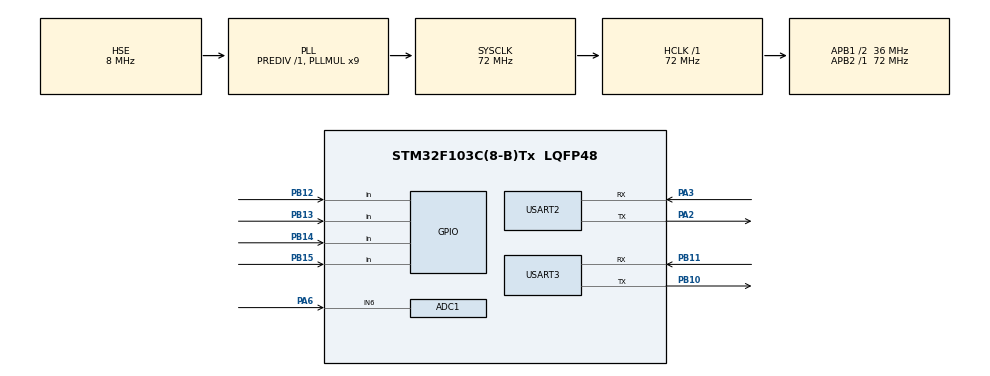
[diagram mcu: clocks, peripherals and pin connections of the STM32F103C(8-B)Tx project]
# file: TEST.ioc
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ADC1.Channel-0\#ChannelRegularConversion=ADC_CHANNEL_6
ADC1.ExternalTrigConv=ADC_EXTERNALTRIGCONV_T3_TRGO
ADC1.NbrOfConversionFlag=1
ADC1.Rank-0\#ChannelRegularConversion=1
ADC1.SamplingTime-0\#ChannelRegularConversion=ADC_SAMPLETIME_1CYCLE_5
ADC1.master=1
Dma.ADC1.2.Direction=DMA_PERIPH_TO_MEMORY
Dma.ADC1.2.Instance=DMA1_Channel1
Dma.ADC1.2.MemDataAlignment=DMA_MDATAALIGN_HALFWORD
Dma.ADC1.2.MemInc=DMA_MINC_ENABLE
Dma.ADC1.2.Mode=DMA_NORMAL
Dma.ADC1.2.PeriphDataAlignment=DMA_PDATAALIGN_HALFWORD
Dma.ADC1.2.PeriphInc=DMA_PINC_DISABLE
Dma.ADC1.2.Priority=DMA_PRIORITY_LOW
Dma.Request0=USART3_RX
Dma.Request1=USART3_TX
Dma.Request2=ADC1
Dma.USART3_RX.0.Direction=DMA_PERIPH_TO_MEMORY
Dma.USART3_RX.0.Instance=DMA1_Channel3
Dma.USART3_RX.0.MemDataAlignment=DMA_MDATAALIGN_BYTE
Dma.USART3_RX.0.MemInc=DMA_MINC_ENABLE
Dma.USART3_RX.0.Mode=DMA_CIRCULAR
Dma.USART3_RX.0.PeriphDataAlignment=DMA_PDATAALIGN_BYTE
Dma.USART3_RX.0.PeriphInc=DMA_PINC_DISABLE
Dma.USART3_RX.0.Priority=DMA_PRIORITY_HIGH
Dma.USART3_TX.1.Direction=DMA_MEMORY_TO_PERIPH
Dma.USART3_TX.1.Instance=DMA1_Channel2
Dma.USART3_TX.1.MemDataAlignment=DMA_MDATAALIGN_BYTE
Dma.USART3_TX.1.MemInc=DMA_MINC_ENABLE
Dma.USART3_TX.1.Mode=DMA_NORMAL
Dma.USART3_TX.1.PeriphDataAlignment=DMA_PDATAALIGN_BYTE
Dma.USART3_TX.1.PeriphInc=DMA_PINC_DISABLE
Dma.USART3_TX.1.Priority=DMA_PRIORITY_HIGH
Mcu.Family=STM32F1
Mcu.Name=STM32F103C(8-B)Tx
Mcu.Package=LQFP48
NVIC.DMA1_Channel1_IRQn=true\:0\:0\:false\:false\:true\:false\:true\:true
NVIC.DMA1_Channel2_IRQn=true\:0\:0\:false\:false\:true\:false\:true\:true
NVIC.DMA1_Channel3_IRQn=true\:0\:0\:false\:false\:true\:false\:true\:true
NVIC.PriorityGroup=NVIC_PRIORITYGROUP_4
NVIC.USART2_IRQn=true\:1\:0\:true\:false\:true\:true\:true\:true
NVIC.USART3_IRQn=true\:1\:0\:true\:false\:true\:false\:true\:true
PA13.Mode=Serial_Wire
PA13.Signal=SYS_JTMS-SWDIO
PA14.Mode=Serial_Wire
PA14.Signal=SYS_JTCK-SWCLK
PA2.Mode=Asynchronous
PA2.Signal=USART2_TX
PA3.Mode=Asynchronous
PA3.Signal=USART2_RX
PA6.Signal=ADCx_IN6
PB10.Mode=Asynchronous
PB10.Signal=USART3_TX
PB11.Mode=Asynchronous
PB11.Signal=USART3_RX
PB12.GPIO_PuPd=GPIO_PULLUP
PB12.Signal=GPIO_Input
PB13.GPIO_PuPd=GPIO_PULLUP
PB13.Signal=GPIO_Input
PB14.GPIO_PuPd=GPIO_PULLUP
PB14.Signal=GPIO_Input
PB15.GPIO_PuPd=GPIO_PULLUP
PB15.Signal=GPIO_Input
PD0-OSC_IN.Mode=HSE-External-Oscillator
PD0-OSC_IN.Signal=RCC_OSC_IN
PD1-OSC_OUT.Mode=HSE-External-Oscillator
PD1-OSC_OUT.Signal=RCC_OSC_OUT
ProjectManager.HeapSize=0x200
ProjectManager.StackSize=0x400
ProjectManager.TargetToolchain=MDK-ARM V5.32
RCC.ADCPresc=RCC_ADCPCLK2_DIV6
RCC.AHBFreq_Value=72000000
RCC.APB1CLKDivider=RCC_HCLK_DIV2
RCC.APB1Freq_Value=36000000
RCC.APB1TimFreq_Value=72000000
RCC.APB2Freq_Value=72000000
RCC.APB2TimFreq_Value=72000000
RCC.HCLKFreq_Value=72000000
RCC.PLLMUL=RCC_PLL_MUL9
RCC.PLLSourceVirtual=RCC_PLLSOURCE_HSE
RCC.SYSCLKFreq_VALUE=72000000
RCC.SYSCLKSource=RCC_SYSCLKSOURCE_PLLCLK
RCC.USBFreq_Value=72000000
SH.ADCx_IN6.0=ADC1_IN6,IN6
TIM3.AutoReloadPreload=TIM_AUTORELOAD_PRELOAD_ENABLE
TIM3.Period=10-1
TIM3.Prescaler=72-1
TIM3.TIM_MasterOutputTrigger=TIM_TRGO_UPDATE
USART2.VirtualMode=VM_ASYNC
USART3.VirtualMode=VM_ASYNC
VP_TIM3_VS_ClockSourceINT.Mode=Internal
board=custom

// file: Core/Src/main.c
/* USER CODE BEGIN Header */
/**
  ******************************************************************************
  * @file           : main.c
  * @brief          : Main program body
  ******************************************************************************
  * @attention
  *
  * Copyright (c) 2025 STMicroelectronics.
  * All rights reserved.
  *
  * This software is licensed under terms that can be found in the LICENSE file
  * in the root directory of this software component.
  * If no LICENSE file comes with this software, it is provided AS-IS.
  *
  ******************************************************************************
  */
/* USER CODE END Header */
#include "main.h"
#include "adc.h"
#include "dma.h"
#include "tim.h"
#include "usart.h"
#include "gpio.h"

/* USER CODE BEGIN Includes */

#include "user.h"

/* USER CODE END Includes */

void SystemClock_Config(void);

int main(void)
{

  /* MCU Configuration--------------------------------------------------------*/

  /* Reset of all peripherals, Initializes the Flash interface and the Systick. */
  HAL_Init();

  /* Configure the system clock */
  SystemClock_Config();

  /* Initialize all configured peripherals */
  MX_GPIO_Init();
  MX_DMA_Init();
  MX_USART3_UART_Init();
  MX_USART2_UART_Init();
  MX_ADC1_Init();
  MX_TIM3_Init();
  /* USER CODE BEGIN 2 */

	User_init();

  /* USER CODE END 2 */

  /* Infinite loop */
  /* USER CODE BEGIN WHILE */
  while (1)
  {
	  Key_use();	// 按键控制处理
	  GetData();	// 获取串口数据
	  putData();	// 显示调节数据
	  Get_ADC();	// 获取电路实际电流
//	  SendData();	// 发送实际参数
    /* USER CODE END WHILE */

  }
}

void SystemClock_Config(void)
{
  RCC_OscInitTypeDef RCC_OscInitStruct = {0};
  RCC_ClkInitTypeDef RCC_ClkInitStruct = {0};
  RCC_PeriphCLKInitTypeDef PeriphClkInit = {0};

  /** Initializes the RCC Oscillators according to the specified parameters
  * in the RCC_OscInitTypeDef structure.
  */
  RCC_OscInitStruct.OscillatorType = RCC_OSCILLATORTYPE_HSE;
  RCC_OscInitStruct.HSEState = RCC_HSE_ON;
  RCC_OscInitStruct.HSEPredivValue = RCC_HSE_PREDIV_DIV1;
  RCC_OscInitStruct.HSIState = RCC_HSI_ON;
  RCC_OscInitStruct.PLL.PLLState = RCC_PLL_ON;
  RCC_OscInitStruct.PLL.PLLSource = RCC_PLLSOURCE_HSE;
  RCC_OscInitStruct.PLL.PLLMUL = RCC_PLL_MUL9;
  if (HAL_RCC_OscConfig(&RCC_OscInitStruct) != HAL_OK)
  {
    Error_Handler();
  }

  /** Initializes the CPU, AHB and APB buses clocks
  */
  RCC_ClkInitStruct.ClockType = RCC_CLOCKTYPE_HCLK|RCC_CLOCKTYPE_SYSCLK
                              |RCC_CLOCKTYPE_PCLK1|RCC_CLOCKTYPE_PCLK2;
  RCC_ClkInitStruct.SYSCLKSource = RCC_SYSCLKSOURCE_PLLCLK;
  RCC_ClkInitStruct.AHBCLKDivider = RCC_SYSCLK_DIV1;
  RCC_ClkInitStruct.APB1CLKDivider = RCC_HCLK_DIV2;
  RCC_ClkInitStruct.APB2CLKDivider = RCC_HCLK_DIV1;

  if (HAL_RCC_ClockConfig(&RCC_ClkInitStruct, FLASH_LATENCY_2) != HAL_OK)
  {
    Error_Handler();
  }
  PeriphClkInit.PeriphClockSelection = RCC_PERIPHCLK_ADC;
  PeriphClkInit.AdcClockSelection = RCC_ADCPCLK2_DIV6;
  if (HAL_RCCEx_PeriphCLKConfig(&PeriphClkInit) != HAL_OK)
  {
    Error_Handler();
  }
}

void Error_Handler(void)
{
  __disable_irq();
  while (1)
  {
  }
}
